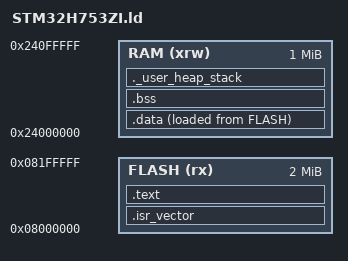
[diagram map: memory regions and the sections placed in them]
ENTRY(Reset_Handler)

_Min_Heap_Size = 0x200;   /* 512 bytes */
_Min_Stack_Size = 0x400;  /* 1KB */

MEMORY
{
    FLASH (rx)  : ORIGIN = 0x08000000, LENGTH = 2048K
    RAM   (xrw) : ORIGIN = 0x24000000, LENGTH = 1024K
}

/* Stack top (first entry in vector table) */
_estack = ORIGIN(RAM) + LENGTH(RAM);

SECTIONS
{
    .isr_vector :
    {
        . = ALIGN(4);
        KEEP(*(.isr_vector))
        . = ALIGN(4);
    } > FLASH

    .text :
    {
        . = ALIGN(4);
        *(.text*)
        *(.rodata*)
        . = ALIGN(4);
        _etext = .;
    } > FLASH

    .data : 
    {
        . = ALIGN(4);
        _sidata = LOADADDR(.data);  /* Source in Flash */
        _sdata = .;                  /* Destination in RAM */
        *(.data*)
        . = ALIGN(4);
        _edata = .;
    } > RAM AT> FLASH

    .bss (NOLOAD) :
    {
        . = ALIGN(4);
        _sbss = .;
        *(.bss*)
        *(COMMON)
        . = ALIGN(4);
        _ebss = .;
    } > RAM

    ._user_heap_stack (NOLOAD) :
    {
        . = ALIGN(8);
        PROVIDE(end = .);
        . = . + _Min_Heap_Size;
        . = . + _Min_Stack_Size;
        . = ALIGN(8);
    } > RAM

    /* Remove debug info */
    /DISCARD/ :
    {
        libc.a (*)
        libm.a (*)
        libgcc.a (*)
    }
}
